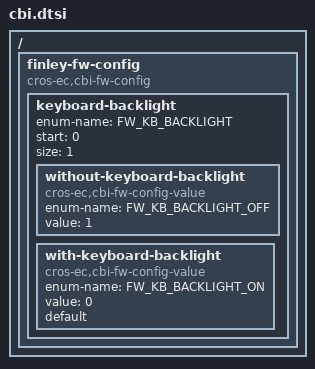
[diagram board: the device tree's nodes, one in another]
/* Copyright 2025 The ChromiumOS Authors
 * Use of this source code is governed by a BSD-style license that can be
 * found in the LICENSE file.
 */

/ {
	finley-fw-config {
		compatible = "cros-ec,cbi-fw-config";

		/*
		 * FW_CONFIG field to indicate which keyboard layout
		 * should be used.
		 */
		keyboard-backlight {
			enum-name = "FW_KB_BACKLIGHT";
			start = <0>;
			size = <1>;

			without-keyboard-backlight {
				compatible = "cros-ec,cbi-fw-config-value";
				enum-name = "FW_KB_BACKLIGHT_OFF";
				value = <1>;
			};
			with-keyboard-backlight {
				compatible = "cros-ec,cbi-fw-config-value";
				enum-name = "FW_KB_BACKLIGHT_ON";
				value = <0>;
				default;
			};
		};
	};
};
